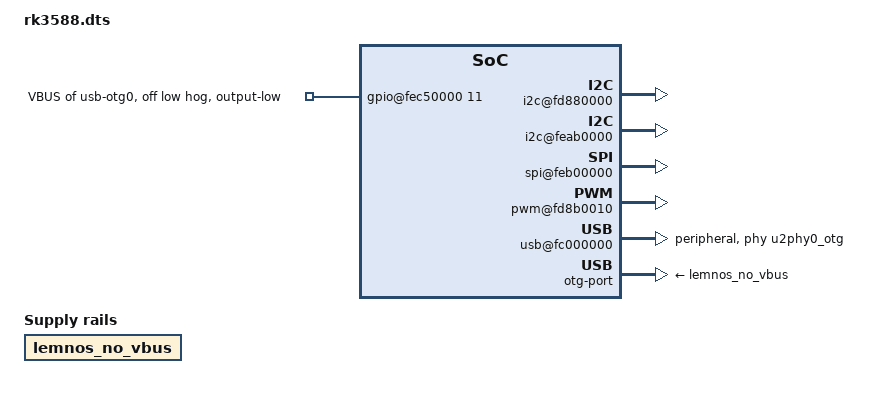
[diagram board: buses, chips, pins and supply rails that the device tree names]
// Generated by `lemnos-ctl tree` from board "rk3588". Do not edit: change the
// board file or the SoC map, and generate again.
// Every fragment says why it is here. Node paths are the base tree's.
/dts-v1/;
/plugin/;
/ {
	// i2c: an I2C bus on the RK3588 (alias i2c0, the name "i2c-0") on GPIO11, GPIO6
	fragment@0 {
		target-path = "/i2c@fd880000";
		__overlay__ {
			status = "okay";
			pinctrl-names = "default";
			pinctrl-0 = <&i2c0m0_xfer>;
		};
	};
	// the runtime name comes out of alias i2c0
	fragment@1 {
		target-path = "/";
		__overlay__ {
			aliases { i2c0 = "/i2c@fd880000"; };
		};
	};
	// i2c: an I2C bus on the RK3588 (alias i2c3, the name "i2c-3") on GPIO48, GPIO49
	fragment@2 {
		target-path = "/i2c@feab0000";
		__overlay__ {
			status = "okay";
			pinctrl-names = "default";
			pinctrl-0 = <&i2c3m0_xfer>;
		};
	};
	// the runtime name comes out of alias i2c3
	fragment@3 {
		target-path = "/";
		__overlay__ {
			aliases { i2c3 = "/i2c@feab0000"; };
		};
	};
	// spi: an SPI controller on the RK3588 (alias spi0, the name "spidev0.0")
	fragment@4 {
		target-path = "/spi@feb00000";
		__overlay__ {
			status = "okay";
		};
	};
	// the runtime name comes out of alias spi0
	fragment@5 {
		target-path = "/";
		__overlay__ {
			aliases { spi0 = "/spi@feb00000"; };
		};
	};
	// pwm: a PWM block on the RK3588 (PWM 1) on GPIO16
	fragment@6 {
		target-path = "/pwm@fd8b0010";
		__overlay__ {
			status = "okay";
			pinctrl-names = "default";
			pinctrl-0 = <&pwm1m0_pins>;
		};
	};
	// block: the VPU121 video codec on the RK3588 (rockchip,rk3588-vpu121)
	fragment@7 {
		target-path = "/video-codec@fdb50000";
		__overlay__ {
			status = "okay";
		};
	};
	// usb-peripheral: the USB 3 DRD (OTG) controller on the RK3588, port 0 (rockchip,rk3588-dwc3); device mode
	fragment@8 {
		target-path = "/usb@fc000000";
		__overlay__ {
			status = "okay";
			dr_mode = "peripheral";
			phys = <&u2phy0_otg>, <&usbdp_phy0 4>;
			phy-names = "usb2-phy", "usb3-phy";
		};
	};
	// needed by usb-otg0 (usb-peripheral): USB 2 PHY 0 (rockchip,rk3588-usb2phy), the USB 2 side of port 0; disabled in the base tree
	fragment@9 {
		target-path = "/syscon@fd5d0000/usb2phy@0";
		__overlay__ {
			status = "okay";
		};
	};
	// the stand-in for a device port's VBUS supply: a fixed regulator with no enable pin, no GPIO and no voltage; it supplies nothing
	fragment@10 {
		target-path = "/";
		__overlay__ {
			lemnos_no_vbus: regulator-lemnos-no-vbus { compatible = "regulator-fixed"; regulator-name = "lemnos-no-vbus"; regulator-min-microvolt = <0>; regulator-max-microvolt = <0>; };
		};
	};
	// needed by usb-otg0 (usb-peripheral): the OTG port of USB 2 PHY 0, the one port 0's controller is wired to (its phys); its phy-supply is replaced by the stand-in, so this PHY drives no VBUS
	fragment@11 {
		target-path = "/syscon@fd5d0000/usb2phy@0/otg-port";
		__overlay__ {
			status = "okay";
			phy-supply = <&lemnos_no_vbus>;
		};
	};
	// needed by usb-otg0 (usb-peripheral): USBDP combo PHY 0 (rockchip,rk3588-usbdp-phy), the SuperSpeed side of port 0; the board names usb3 (its phys, PHY_TYPE_USB3)
	fragment@12 {
		target-path = "/phy@fed80000";
		__overlay__ {
			status = "okay";
		};
	};
	// disabled: base "usb-gpio-vbus" /vcc5v0-otg-vbus: the VBUS regulator of usb-otg0 is switched by gpio:gpio4:11; its phy-supply is the stand-in, so nothing uses it and the hog holds gpio:gpio4:11 at its off level
	fragment@13 {
		target-path = "/vcc5v0-otg-vbus";
		__overlay__ {
			status = "disabled";
		};
	};
	// gpio-hog: gpio:gpio4:11 is low from power-on, until the kernel takes the line
	fragment@14 {
		target-path = "/pinctrl/gpio@fec50000";
		__overlay__ {
			lemnos-hog-11 { gpio-hog; gpios = <11 0>; output-low; line-name = "VBUS of usb-otg0, off low"; };
		};
	};
};
